# FLASH register map
Vendor: Texas Instruments
Registers are 32-bit, read-write, no defined reset value unless marked. A register's access mark holds for its fields unless they carry their own. Offsets are as the file gives them; [hi:lo] are bit positions; lines under a group give offsets from that group; {n}, {i} and the like mark numbered series; 'fields as' and 'values as' point back to an identical list.

## FLASH (part 2 of 2) — This is the MMR space for the flash wrapper. The flash wrapper is targeting multiple microcontroller platforms. The flash wrapper is a module that manages complex flash read, program and erase memory operations. The system is also given direct access to read flash memory contents directly for each instantiated flash bank through FBAP ports.
{0x30+4i} CMDDATA{i} (i=20..23) — Command Data Register {i} This register forms the data for a command. For DATAWIDTH == 128: This register represents bits {32i-609}:{32i-640} of flash word data register 5. This register is blocked for writes after a 1 is written to the CMDEXEC register and prior to STATCMD.DONE being set by the flash wrapper hardware. This register is used to aggregate masking for bits that do not require additional program pulses during program operations, and will be written to all 1 after the completion of all flash wrapper commands. Use cases for the CMDDATA* registers are as follows: 1) Program - These registers contain the data to be programmed. 2) Erase - These registers are not used.
  [31:0] VAL — A 32-bit data value is placed in this field.
    0xFFFFFFFF=MAXIMUM (Maximum value of [VAL]); 0=MINIMUM (Minimum value of [VAL])
0x80 CPU_CONNECT_0 — Directly connect peripheral publisher port to application processor
  [1] CPUSS0_CONN — CPUSS0 connect bit.
    0=UNCONNECTED (The CPU is not connected.); 1=CONNECTED (The CPU is connected.)
0x90 CMDDATA24 — Command Data Register 24 This register forms the data for a command. For DATAWIDTH == 128: This register represents bits 31:0 of flash word data register 6. This register is blocked for writes after a 1 is written to the CMDEXEC register and prior to STATCMD.DONE being set by the flash wrapper hardware. This register is used to aggregate masking for bits that do not require additional program pulses during program operations, and will be written to all 1 after the completion of all flash wrapper commands. Use cases for the CMDDATA* registers are as follows: 1) Program - These registers contain the data to be programmed. 2) Erase - These registers are not used.
  fields as CMDDATA20
0x94 CMDDATA25 — Command Data Register 25 This register forms the data for a command. For DATAWIDTH == 128: This register represents bits 63:32 of flash word data register 6. This register is blocked for writes after a 1 is written to the CMDEXEC register and prior to STATCMD.DONE being set by the flash wrapper hardware. This register is used to aggregate masking for bits that do not require additional program pulses during program operations, and will be written to all 1 after the completion of all flash wrapper commands. Use cases for the CMDDATA* registers are as follows: 1) Program - These registers contain the data to be programmed. 2) Erase - These registers are not used.
  fields as CMDDATA20
0x98 CMDDATA26 — Command Data Register 26 This register forms the data for a command. For DATAWIDTH == 128: This register represents bits 95:64 of flash word data register 6. This register is blocked for writes after a 1 is written to the CMDEXEC register and prior to STATCMD.DONE being set by the flash wrapper hardware. This register is used to aggregate masking for bits that do not require additional program pulses during program operations, and will be written to all 1 after the completion of all flash wrapper commands. Use cases for the CMDDATA* registers are as follows: 1) Program - These registers contain the data to be programmed. 2) Erase - These registers are not used..
  fields as CMDDATA20
0x9C CMDDATA27 — Command Data Register 27 This register forms the data for a command. For DATAWIDTH == 128: This register represents bits 127:96 of flash word data register 6. This register is blocked for writes after a 1 is written to the CMDEXEC register and prior to STATCMD.DONE being set by the flash wrapper hardware. This register is used to aggregate masking for bits that do not require additional program pulses during program operations, and will be written to all 1 after the completion of all flash wrapper commands. Use cases for the CMDDATA* registers are as follows: 1) Program - These registers contain the data to be programmed. 2) Erase - These registers are not used.
  fields as CMDDATA20
{0x30+4i} CMDDATA{i} (i=28..31) — Command Data Register {i} This register forms the data for a command. For DATAWIDTH == 128: This register represents bits {32i-865}:{32i-896} of flash word data register 7. This register is blocked for writes after a 1 is written to the CMDEXEC register and prior to STATCMD.DONE being set by the flash wrapper hardware. This register is used to aggregate masking for bits that do not require additional program pulses during program operations, and will be written to all 1 after the completion of all flash wrapper commands. Use cases for the CMDDATA* registers are as follows: 1) Program - These registers contain the data to be programmed. 2) Erase - These registers are not used.
  fields as CMDDATA20
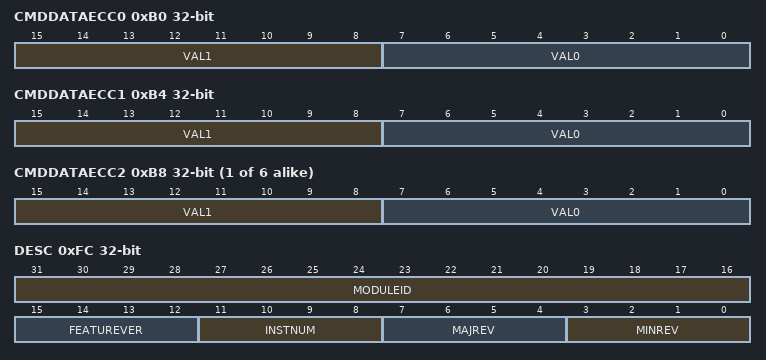
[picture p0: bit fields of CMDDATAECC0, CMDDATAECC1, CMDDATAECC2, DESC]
0xB0 CMDDATAECC0 — Command Data Register 0 This register forms the ECC portion of the data for a command. This ECC data in this register covers flash data register 0. The hardware ECC generation in flash wrapper can be overridden and ECC data developed elsewhere can be used. ECC data is placed in this register. This register is blocked for writes after a 1 is written to the CMDEXEC register and prior to STATCMD.DONE being set by the flash wrapper hardware. Use cases for the CMDDATA* registers are as follows: 1) Program - These registers contain the data to be programmed. 2) Erase - These registers are not used. This register is used to aggregate masking for bits that do not require additional program pulses during program operations, and will be written to all 1 after the completion of all flash wrapper commands.
  [15:8] VAL1 — ECC data for bits 127:64 of the data is placed here.
    255=MAXIMUM (Maximum value); 0=MINIMUM (Minimum value)
  [7:0] VAL0 — ECC data for bits 63:0 of the data is placed here.
    255=MAXIMUM (Maximum value); 0=MINIMUM (Minimum value)
0xB4 CMDDATAECC1 — Command Data Register 1 This register forms the ECC portion of the data for a command. This ECC data in this register covers flash data register 0. The hardware ECC generation in flash wrapper can be overridden and ECC data developed elsewhere can be used. ECC data is placed in this register. This register is blocked for writes after a 1 is written to the CMDEXEC register and prior to STATCMD.DONE being set by the flash wrapper hardware. Use cases for the CMDDATA* registers are as follows: 1) Program - These registers contain the data to be programmed. 2) Erase - These registers are not used. This register is used to aggregate masking for bits that do not require additional program pulses during program operations, and will be written to all 1 after the completion of all flash wrapper commands.
  fields as CMDDATAECC0
{0xB0+4i} CMDDATAECC{i} (i=2..7) — Command Data Register {i} This register forms the ECC portion of the data for a command. This ECC data in this register covers flash data register {i}. The hardware ECC generation in flash wrapper can be overridden and ECC data developed elsewhere can be used. ECC data is placed in this register. This register is blocked for writes after a 1 is written to the CMDEXEC register and prior to STATCMD.DONE being set by the flash wrapper hardware. Use cases for the CMDDATA* registers are as follows: 1) Program - These registers contain the data to be programmed. 2) Erase - These registers are not used. This register is used to aggregate masking for bits that do not require additional program pulses during program operations, and will be written to all 1 after the completion of all flash wrapper commands.
  fields as CMDDATAECC0
0xD0 CMDWEPROTA — Command WriteErase Protect A Register This register allows the first 32 sectors of the main region to be protected from program or erase, with 1 bit protecting each sector. If the main region size is smaller than 32 sectors, then this register provides protection for the whole region. This register is blocked for writes after a 1 is written to the CMDEXEC register and prior to STATCMD.DONE being set by the flash wrapper hardware. In addition, this register is used to aggregate masking for sectors that do not require additional erase pulses during bank erase operations, and will be written to all 1 after the completion of all flash wrapper commands.
  [31:0] VAL — Each bit protects 1 sector. bit [0]: When 1, sector 0 of the flash memory will be protected from program and erase. bit [1]: When 1, sector 1 of the flash memory will be protected from program and erase. : : bit [31]: When 1, sector 31 of the flash memory will be protected from program and erase.
    values as CMDDATA20.VAL
0xD4 CMDWEPROTB — Command WriteErase Protect B Register This register allows main region sectors to be protected from program and erase. Each bit corresponds to a group of 8 sectors. There are multiple cases for how these protect bits are applied: 1. Single-bank system, CMDWEPROTA register present: The first 32 sectors are protected via the CMDWEPROTA register. Thus, the protection given by the bits in CMDWEPROTB begin with sector 32. 2. Single-bank system, CMDWEPROTA register not present: The protection given by the bits in CMDWEPROTB begin with sector 0. 3. Multi-bank system, CMDWEPROTA register present - Bank 0: The first 32 sectors of bank 0 are protected via the CMDWEPROTA register. Thus, only bits 4 and above of CMDWEPROTB would be applicable to bank 0. The protection of bit 4 and above would begin at sector 32. Bits 3:0 of WEPROTB are ignored for bank 0. 4. Multi-bank system, CMDWEPROTA register present, Banks 1-N: For banks other than bank 0 in a multi-bank system, CMDWEPROTA has no effect, so the bits in CMDWEPROTB will protect these banks starting from sector 0. 5. Multi-bank system, CMDWEPROTA register not present: The bits in CMDWEPROTB will protect any of the banks starting from sector 0. This register is blocked for writes after a 1 is written to the CMDEXEC register and prior to STATCMD.DONE being set by the flash wrapper hardware. In addition, this register is used to aggregate masking for sectors that do not require additional erase pulses during bank erase operations, and will be written to all 1 after the completion of all flash wrapper commands.
  [31:0] VAL — Each bit protects a group of 8 sectors. When a bit is 1, the associated 8 sectors in the flash will be protected from program and erase. A maximum of 256 sectors can be protected with this register.
    values as CMDDATA20.VAL
0xD8 CMDWEPROTC — Command WriteErase Protect C Register This register allows main region sectors to be protected from program and erase. Each bit corresponds to a group of 8 sectors. This register extends the protection bits from the CMDWEPROTB register to cover bank sizes larger than 32*8=256 sectors. This register is blocked for writes after a 1 is written to the CMDEXEC register and prior to STATCMD.DONE being set by the flash wrapper hardware. In addition, this register is used to aggregate masking for sectors that do not require additional erase pulses during bank erase operations, and will be written to all 1 after the completion of all flash wrapper commands.
  [31:0] VAL — Each bit protects a group of 8 sectors. When a bit is 1, the associated 8 sectors in the flash will be protected from program and erase. Note that the sectors protected with this register start at sector 256 in the flash, where the sectors protected by the CMDWEPROTB register end.
    values as CMDDATA20.VAL
0xE0 EVT_MODE ro — Event mode register. It is used to select whether each line is disabled, in software mode (software clears the RIS) or in hardware mode (hardware clears the RIS).
  [1:0] INT0_CFG — Event line mode select for peripheral event
    0=DISABLE (The interrupt or event line is disabled.); 1=SOFTWARE (The interrupt or event line is in software mode. Software must clear the RIS.); 2=HARDWARE (The interrupt or event line is in hardware mode. Hardware must clear the RIS.)
0xFC DESC ro — Hardware Version Description Register: This register identifies the flash wrapper hardware version and feature set used.
  [31:16] MODULEID
    0xFFFF=MAXIMUM (Highest possible value); 0=MINIMUM (Smallest value)
  [15:12] FEATUREVER — Feature set
    15=MAXIMUM (Maximum Value); 0=MINIMUM (Minimum Value)
  [11:8] INSTNUM — Instance number
    15=MAXIMUM (Highest possible value); 0=MINIMUM (Smallest value)
  [7:4] MAJREV — Major Revision
    values as INSTNUM
  [3:0] MINREV — Minor Revision
    values as INSTNUM
0x100 TRIMCTL — Allows control of the application of bank/pump trim values.
  [0] ENABLE — Indicate that Bank and Pump trim values are valid.
    0=INVALID (Trim data is not valid); 1=VALID (Trim data is valid)
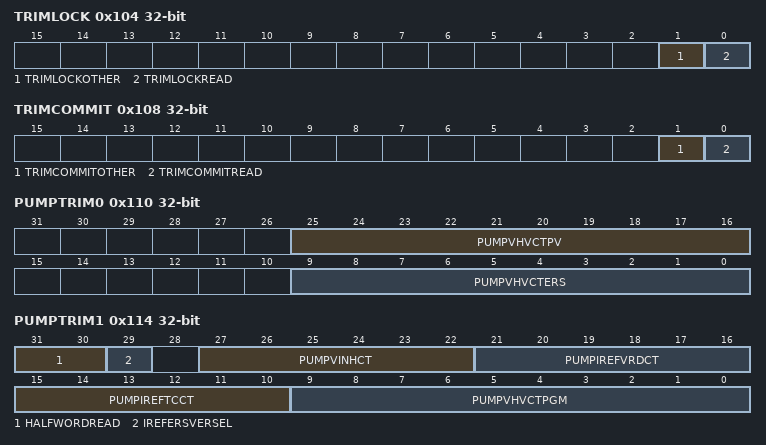
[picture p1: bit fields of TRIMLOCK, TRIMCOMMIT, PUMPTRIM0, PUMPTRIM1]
0x104 TRIMLOCK — Trim Lock Register When set PUMPTRIM* and BANK*TRIM* registers are locked and cannot be written.
  [1] TRIMLOCKOTHER — This bit controls the PUMPTRIM and BANK*TRIM registers.
    0=UNLOCKED (*TRIM registers are open for write.); 1=LOCKED (*TRIM registers are locked from write)
  [0] TRIMLOCKREAD — This bit controls the PUMPTRIMREAD and BANK*TRIMREAD registers.
    0=UNLOCKED (*TRIMREAD registers are open for write.); 1=LOCKED (*TRIMREAD registers are locked from write)
0x108 TRIMCOMMIT — Trim Commit Register When bits in this register are set, all associated trim registers (including TRIMCTL, TRIMLOCK and this register) are locked from update. Only a reset will unlock this register.
  [1] TRIMCOMMITOTHER — This bit controls the PUMPTRIM and BANK*TRIM registers.
    0=UNCOMMITTED (*TRIM registers are not committed.); 1=COMMITTED (*TRIM registers are committed)
  [0] TRIMCOMMITREAD — This bit controls the PUMPTRIMREAD and BANK*TRIMREAD registers.
    0=UNCOMMITTED (*TRIMREAD registers are not committed.); 1=COMMITTED (*TRIMREAD registers are committed)
0x110 PUMPTRIM0 — Pump Trim 0 Register. This register contains pump trim values associated with program and erase.
  [25:16] PUMPVHVCTPV — VHVCT pump trim value for program verify
    0x3FF=MAXIMUM (Maximum value of [PUMPVHVCTPV]); 0=MINIMUM (Minimum value of [PUMPVHVCTPV])
  [9:0] PUMPVHVCTERS — VHVCT pump trim value for erase
    0x3FF=MAXIMUM (Maximum value of [PUMPVHVCTERS]); 0=MINIMUM (Minimum value of [PUMPVHVCTERS])
0x110 CMDWEPROTNM — Command WriteErase Protect Non-Main Register This register allows non-main region region sectors to be protected from program and erase. Each bit corresponds to 1 sector. This register is blocked for writes after a 1 is written to the CMDEXEC register and prior to STATCMD.DONE being set by the flash wrapper hardware. In addition, this register is used to aggregate masking for sectors that do not require additional erase pulses during bank erase operations, and will be written to all 1 after the completion of all flash wrapper commands.
  [31:0] VAL — Each bit protects 1 sector. bit [0]: When 1, sector 0 of the non-main region will be protected from program and erase. bit [1]: When 1, sector 1 of the non-main region will be protected from program and erase. : : bit [31]: When 1, sector 31 of the non-main will be protected from program and erase.
    values as CMDDATA20.VAL
0x114 PUMPTRIM1 — Pump Trim 1 Register. This register contains pump trim values associated with program and erase.
  [31:30] HALFWORDREAD — NoWrapper half-word read disable
    3=HALFWORDDIS (Half word read disabled for EraseVerify Half word read disabled for ReadVerify/ProgramVerify); 2=HALFWORDEN_PVRV (Half word read disabled for EraseVerify Half word read enabled for ReadVerify/ProgramVerify); 1=HALFWORDEN_EV (Half word read enabled for EraseVerify Half word read disabled for ReadVerify/ProgramVerify); 0=HALFWORDEN_EV_PVRV (Half word read enabled for EraseVerify Half word read enabled for ReadVerify/ProgramVerify)
  [29] IREFERSVERSEL — Indicates low or high setting for IREF used for erase verify mode in all banks
    0=LOWIREF (IREF set to lower value (higher value * 2/3)); 1=HIGHIREF (IREF set to higher value.)
  [27:22] PUMPVINHCT — VINHCT pump trim value
    63=MAXIMUM (Maximum value of [PUMPVINHCT]); 0=MINIMUM (Minimum value of [PUMPVINHCT])
  [21:16] PUMPIREFVRDCT — IREFVRDCT pump trim value
    31=MAXIMUM (Maximum value of [PUMPIREFVRDCT]); 0=MINIMUM (Minimum value of [PUMPIREFVRDCT])
  [15:10] PUMPIREFTCCT — IREFTCCT pump trim value
    31=MAXIMUM (Maximum value of [PUMPIREFTCCT]); 0=MINIMUM (Minimum value of [PUMPIREFTCCT])
  [9:0] PUMPVHVCTPGM — VHVCT pump trim value for program
    0x3FF=MAXIMUM (Maximum value of [PUMPVHVCTPGM]); 0=MINIMUM (Minimum value of [PUMPVHVCTPGM])
0x114 CMDWEPROTTR — Command WriteErase Protect Trim Register This register allows trim region sectors to be protected from program and erase. Each bit corresponds to 1 sector. This register is blocked for writes after a 1 is written to the CMDEXEC register and prior to STATCMD.DONE being set by the flash wrapper hardware. In addition, this register is used to aggregate masking for sectors that do not require additional erase pulses during bank erase operations, and will be written to all 1 after the completion of all flash wrapper commands.
  [31:0] VAL — Each bit protects 1 sector. bit [0]: When 1, sector 0 of the engr region will be protected from program and erase. bit [1]: When 1, sector 1 of the engr region will be protected from program and erase. : : bit [31]: When 1, sector 31 of the engr region will be protected from program and erase.
    values as CMDDATA20.VAL
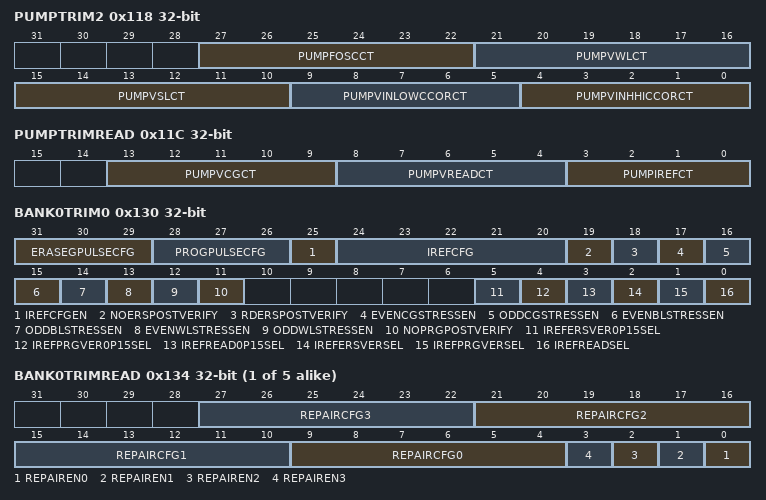
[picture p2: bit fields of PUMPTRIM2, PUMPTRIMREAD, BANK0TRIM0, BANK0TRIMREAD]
0x118 PUMPTRIM2 — Pump Trim 2 Register. This register contains pump trim values associated with program and erase.
  [27:22] PUMPFOSCCT — FOSCCT pump trim value
    63=MAXIMUM (Maximum value of [PUMPFOSCCT]); 0=MINIMUM (Minimum value of [PUMPFOSCCT])
  [21:16] PUMPVWLCT — VWLCT pump trim value
    63=MAXIMUM (Maximum value of [PUMPVWLCT]); 0=MINIMUM (Minimum value of [PUMPVWLCT])
  [15:10] PUMPVSLCT — VSLCT pump trim value
    63=MAXIMUM (Maximum value of [PUMPVSLCT]); 0=MINIMUM (Minimum value of [PUMPVSLCT])
  [9:5] PUMPVINLOWCCORCT — VINLOWCCORCT pump trim value
    31=MAXIMUM (Maximum value of [PUMPVINLOWCCORCT]); 0=MINIMUM (Minimum value of [PUMPVINLOWCCORCT])
  [4:0] PUMPVINHHICCORCT — VINHHICCORCT pump trim value
    31=MAXIMUM (Maximum value of [PUMPVINHHICCORCT]); 0=MINIMUM (Minimum value of [PUMPVINHHICCORCT])
0x118 CMDWEPROTEN — Command WriteErase Protect Engr Register This register allows engr region sectors to be protected from program and erase. Each bit corresponds to 1 sector. This register is blocked for writes after a 1 is written to the CMDEXEC register and prior to STATCMD.DONE being set by the flash wrapper hardware. In addition, this register is used to aggregate masking for sectors that do not require additional erase pulses during bank erase operations, and will be written to all 1 after the completion of all flash wrapper commands.
  fields as CMDWEPROTTR
0x11C PUMPTRIMREAD — Pump Read Trim Register. This register contains pump trim values which apply to flash reads.
  [13:9] PUMPVCGCT — VCGCT pump trim value
    31=MAXIMUM (Maximum value of [PUMPVCGCT]); 0=MINIMUM (Minimum value of [PUMPVCGCT])
  [8:4] PUMPVREADCT — VREADCT pump trim value
    31=MAXIMUM (Maximum value of [PUMPVREADCT]); 0=MINIMUM (Minimum value of [PUMPVREADCT])
  [3:0] PUMPIREFCT — IREFCT pump trim value
    15=MAXIMUM (Maximum value of [PUMPIREFCT]); 0=MINIMUM (Minimum value of [PUMPIREFCT])
0x130 BANK0TRIM0 — Bank 0 Trim 0 Register. Contains bits [31:0] of the bank 0 trim.
  [31:29] ERASEGPULSECFG — Configures the length of the erase pulse. By default, the erase pulse time is fixed. When the SKIPPOSTVERIFY bit is set, the configuration in this field is used for the erase pulse length.
    7=USE50MS (Use 50ms for the erase pulse time); 6=USE25MS (Use 25ms for the erase pulse time); 5=USE700MS (Use 700ms for the erase pulse time); 4=USE500MS (Use 500ms for the erase pulse time); 3=USE400MS (Use 400ms for the erase pulse time); 2=USE300MS (Use 300ms for the erase pulse time); 1=USE200MS (Use 200ms for the erase pulse time); 0=USE100MS (Use 100ms for the erase pulse time)
  [28:26] PROGPULSECFG — Configures the length of the program pulse. By default, the program pulse time is fixed. When the SKIPPOSTVERIFY bit is set, the configuration in this field is used for the program pulse length.
    7=USE1XDEFAULT (Use 1.0 X the default, fixed program pulse time); 6=USE0P5XDEFAULT (Use 0.5 X the default, fixed program pulse time); 5=USE5XDEFAULT (Use 5.0 X the default, fixed program pulse time); 4=USE4XDEFAULT (Use 4.0 X the default, fixed program pulse time); 3=USE3XDEFAULT (Use 3.0 X the default, fixed program pulse time); 2=USE2P5XDEFAULT (Use 2.5 X the default, fixed program pulse time); 1=USE2XDEFAULT (Use 2.0 X the default, fixed program pulse time); 0=USE1P5XDEFAULT (Use 1.5 X the default, fixed program pulse time)
  [25] IREFCFGEN — Enables override of IREF configuration. By default, this is controlled by the mode setting in the bank. If this bit is set, the mode setting will be ignored, and the value encoded into the IREFCFG field will be used to configure the IREF on the reference side.
    0=DISABLED (Feature disabled); 1=ENABLED (Feature enabled)
  [24:20] IREFCFG — Configures IREF used for read operation
    16=USE3XIREF (Adds 3.00*IREF (nominally 4uA to bank) to the IREF current on the reference side); 8=USE2XIREF (Adds 2.00*IREF (nominally 4uA to bank) to the IREF current on the reference side); 4=USE1XIREF (Adds 1.00*IREF (nominally 4uA to bank) to the IREF current on the reference side); 2=USE0P5XIREF (Adds 0.50*IREF (nominally 4uA to bank) to the IREF current on the reference side); 1=USE0P25XIREF (Adds 0.25*IREF (nominally 4uA to bank) to the IREF current on the reference side); 0=DEFAULTIREF (Uses default IREF on the reference side)
  [19] NOERSPOSTVERIFY — Do not do a post verify after erase.
    0=DISABLED (Feature disabled); 1=ENABLED (Feature enabled)
  [18] RDERSPOSTVERIFY — Use READ mode for erase verify operations.
    0=DISABLED (Feature disabled); 1=ENABLED (Feature enabled)
  [17] EVENCGSTRESSEN — Even control gate stress enable
    0=DISABLED (Feature disabled); 1=ENABLED (Feature enabled)
  [16] ODDCGSTRESSEN — Odd control gate stress enable
    0=DISABLED (Feature disabled); 1=ENABLED (Feature enabled)
  [15] EVENBLSTRESSEN — Even bit line stress enable
    0=DISABLED (Feature disabled); 1=ENABLED (Feature enabled)
  [14] ODDBLSTRESSEN — Odd bit line stress enable
    0=DISABLED (Feature disabled); 1=ENABLED (Feature enabled)
  [13] EVENWLSTRESSEN — Even word line stress enable
    0=DISABLED (Feature disabled); 1=ENABLED (Feature enabled)
  [12] ODDWLSTRESSEN — Odd word line stress enable
    0=DISABLED (Feature disabled); 1=ENABLED (Feature enabled)
  [11] NOPRGPOSTVERIFY — Do not do a post verify after program.
    0=DISABLED (Feature disabled); 1=ENABLED (Feature enabled)
  [5] IREFERSVER0P15SEL — Indicates low or high setting for IREF used for erase verify mode. High setting is 15% higher than low setting.
    values as PUMPTRIM1.IREFERSVERSEL
  [4] IREFPRGVER0P15SEL — Indicates low or high setting for IREF used for program verify mode. High setting is 15% higher than low setting.
    values as PUMPTRIM1.IREFERSVERSEL
  [3] IREFREAD0P15SEL — Indicates low or high setting for IREF used for read modes. High setting is 15% higher than low setting.
    0=LOWIREF (IREF set to nominal value); 1=HIGHIREF (IREF set to nominal value + 10%.)
  [2] IREFERSVERSEL — Indicates low or high setting for IREF used for erase verify mode. High setting is 50% higher than low setting.
    values as PUMPTRIM1.IREFERSVERSEL
  [1] IREFPRGVERSEL — Indicates low or high setting for IREF used for program verify mode. High setting is 50% higher than low setting.
    values as PUMPTRIM1.IREFERSVERSEL
  [0] IREFREADSEL — Indicates low or high setting for IREF used for read modes. High setting is 50% higher than low setting.
    values as PUMPTRIM1.IREFERSVERSEL
{0x134+0x10*i} BANK{i}TRIMREAD (i=0..4) — Bank {i} Read Trim Register. Contains repair trim bits for bank {i}.
  [6n+9:6n+4] REPAIRCFG{n} (n=0..3) — Repair Configure {n} Configures repair for bank data bits {36n+35}:{36n} (if ecc) or {32n+31}:{32n} (if no ecc). This field indicates which of the 36 (if ecc) or 32 (if no ecc) bits in the bank data word is replaced with a redundant bit for repair.
    35=MAXIMUM (Maximum value of [REPAIRCFG{n}]); 0=MINIMUM (Minimum value of [REPAIRCFG{n}])
  [n] REPAIREN{n} (n=0..3) — Repair Enable {n} Enables repair for bank data bits {36n+35}:{36n} (if ecc) or {32n+31}:{32n} (if no ecc)
    0=DISABLE; 1=ENABLE
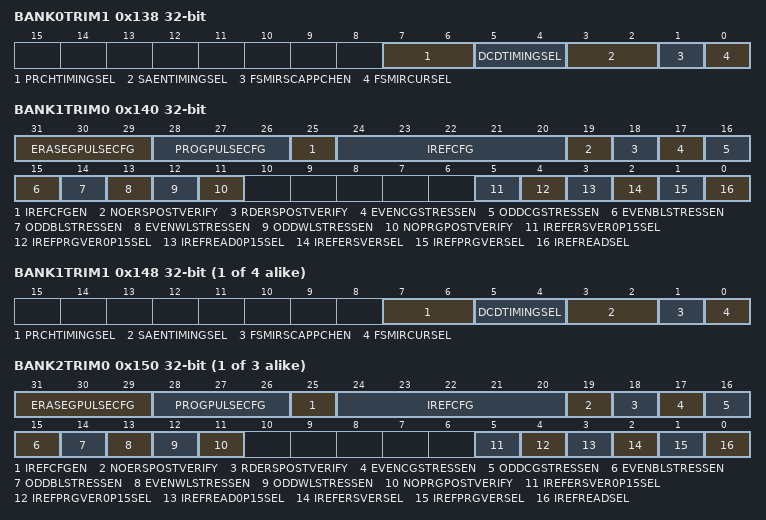
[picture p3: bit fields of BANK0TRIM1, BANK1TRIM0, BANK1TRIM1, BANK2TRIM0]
0x138 BANK0TRIM1 — Bank 0 Trim 1 Register. Contains bits [39:32] of the bank 0 trim (MP bank only)
  [7:6] PRCHTIMINGSEL — Select delay for bitline precharge
    3=FASTTIMING (Faster timing by 1x time step (1 x 0.4 ns at worst timing corner)); 2=NOMINAL (Nominal timing delay); 1=SLOWTIMING (Slower timing by 1x time step (1 x 0.4 ns at worst timing corner)); 0=SLOWX2TIMING (Slower timing by 2x time step (2 x 0.4 ns at worst timing corner))
  [5:4] DCDTIMINGSEL — Select delay for address decode.
    0=SLOWX2TIMING (Slower timing by 2x time step (2 x 0.4 ns at worst timing corner)); 3=FASTTIMING (Faster timing by 1x time step (1 x 0.4 ns at worst timing corner)); 1=SLOWTIMING (Slower timing by 1x time step (1 x 0.4 ns at worst timing corner)); 2=NOMINAL (Nominal timing delay)
  [3:2] SAENTIMINGSEL — Select delay for sense amp enable
    3=FASTX2TIMING (Faster timing by 2x time step (2 x 0.5 ns at worst timing corner)); 2=FASTTIMING (Faster timing by 1x time step (1 x 0.5 ns at worst timing corner)); 0=SLOWTIMING (Slower timing by 1x time step (1 x 0.5 ns at worst timing corner)); 1=NOMTIMING (Nominal timing delay)
  [1] FSMIRSCAPPCHEN — Enable for stabilization capacitance pre-charge at fast startup current mirror
    0=DISABLE; 1=ENABLE
  [0] FSMIRCURSEL — Select for quiescent current at fast startup current mirror
    0=NOMCUR (Enables nominal quiescent current); 1=LOWCUR (Enables low quiescent current)
0x140 BANK1TRIM0 — Bank 1 Trim 0 Register. Contains bits [31:0] of the bank 0 trim.
  fields as BANK0TRIM0
{0x138+0x10*i} BANK{i}TRIM1 (i=1..4) — Bank {i} Trim 1 Register. Contains bits [39:32] of the bank 0 trim (MP bank only)
  [7:6] PRCHTIMINGSEL — Select delay for bitline precharge
    values as BANK0TRIM1.PRCHTIMINGSEL
  [5:4] DCDTIMINGSEL — Select delay for address decode.
    values as BANK0TRIM1.PRCHTIMINGSEL
  [3:2] SAENTIMINGSEL — Select delay for sense amp enable
    3=FASTX2TIMING (Faster timing by 2x time step (2 x 0.5 ns at worst timing corner)); 2=FASTTIMING (Faster timing by 1x time step (1 x 0.5 ns at worst timing corner)); 1=NOMTIMING (Nominal timing delay); 0=SLOWTIMING (Slower timing by 1x time step (1 x 0.5 ns at worst timing corner))
  [1] FSMIRSCAPPCHEN — Enable for stabilization capacitance pre-charge at fast startup current mirror
    0=DISABLE; 1=ENABLE
  [0] FSMIRCURSEL — Select for quiescent current at fast startup current mirror
    values as BANK0TRIM1.FSMIRCURSEL
{0x130+0x10*i} BANK{i}TRIM0 (i=2..4) — Bank {i} Trim 0 Register. Contains bits [31:0] of the bank {i} trim.
  fields as BANK0TRIM0
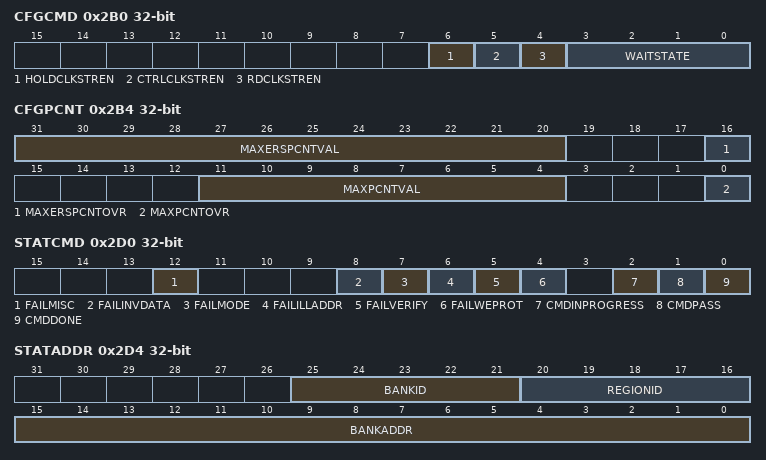
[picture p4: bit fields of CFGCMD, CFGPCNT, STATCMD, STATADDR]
0x2B0 CFGCMD — Command Configuration Register This register configures specific capabilities of the state machine for related to the execution of a command. This register is blocked for writes after CMDEXEC is written to a 1 and prior to STATCMD.DONE being set by the hardware to indicate that command execution has completed.
  [6] HOLDCLKSTREN — Enable pulse stretching for the clocking of the hold latches for inputs to the flash bank. This effectively divides the flash controller internal clock in order to create a 50/50 duty cycle clock for hold latching.
    0=DISABLE; 1=ENABLE
  [5] CTRLCLKSTREN — Enable pulse stretching when generating a control clock to the flash bank from the flash wrapper. This effectively divides the control clock driven to the bank in order to avoid minimum pulse width requirements at the bank.
    0=DISABLE; 1=ENABLE
  [4] RDCLKSTREN — Enable pulse stretching when generating a read clock to the flash bank from the flash wrapper. This effectively divides the read clock driven to the bank in order to avoid minimum pulse width requirements at the bank.
    0=DISABLE; 1=ENABLE
  [3:0] WAITSTATE — Wait State setting for verify reads
    15=MAXIMUM (Maximum value); 0=MINIMUM (Minimum value)
0x2B4 CFGPCNT — Pulse Counter Configuration Register This register allows further configuration of maximum pulse counts for program and erase operations. This register is blocked for writes after a 1 is written to the CMDEXEC register and prior to STATCMD.DONE being set by the flash wrapper hardware.
  [31:20] MAXERSPCNTVAL — Override maximum pulse count for erase with this value. If MAXERSPCNTOVR = 0, then this field is ignored. If MAXERSPCNTOVR = 1, then this value will be used to override the max pulse count for erase.
    0xFFF=MAXIMUM (Maximum value); 0=MINIMUM (Minimum value)
  [16] MAXERSPCNTOVR — Override hard-wired maximum pulse count for erase. If set, then the value in MAXERSPCNTVAL will be used as the max pulse count for erase operations. By default, this bit is 0, and a hard-wired max pulse count is used.
    0=DEFAULT (Use hard-wired (default) value for maximum pulse count); 1=OVERRIDE (Use value from MAXERSPCNTVAL field as maximum erase pulse count)
  [11:4] MAXPCNTVAL — Override maximum pulse counter with this value. If MAXPCNTOVR = 0, then this field is ignored. If MAXPCNTOVR = 1 and MAXERSPCNTOVR = 0, then this value will be used to override the max pulse count for both program and erase. Full max value will be {4'h0, MAXPCNTVAL} . If MAXPCNTOVR = 1 and MAXERSPCNTOVR = 1, then this value will be used to override the max pulse count for program only. Full max value will be {4'h0, MAXPCNTVAL}.
    255=MAXIMUM (Maximum value); 0=MINIMUM (Minimum value)
  [0] MAXPCNTOVR — Override hard-wired maximum pulse count. If MAXERSPCNTOVR is not set, then setting this value alone will override the max pulse count for both program and erase. If MAXERSPCNTOVR is set, then this bit will only control the max pulse count setting for program. By default, this bit is 0, and a hard-wired max pulse count is used.
    0=DEFAULT (Use hard-wired (default) value for maximum pulse count); 1=OVERRIDE (Use value from MAXPCNTVAL field as maximum puse count)
0x2D0 STATCMD ro — Command Status Register This register contains status regarding completion and errors of command execution.
  [12] FAILMISC — Command failed due to error other than write/erase protect violation or verify error. This is an extra bit in case a new failure mechanism is added which requires a status bit.
    0=STATNOFAIL (No Fail); 1=STATFAIL (Fail)
  [8] FAILINVDATA — Program command failed because an attempt was made to program a stored 0 value to a 1.
    0=STATNOFAIL (No Fail); 1=STATFAIL (Fail)
  [7] FAILMODE — Command failed because a bank has been set to a mode other than READ. Program and Erase commands cannot be initiated unless all banks are in READ mode.
    0=STATNOFAIL (No Fail); 1=STATFAIL (Fail)
  [6] FAILILLADDR — Command failed due to the use of an illegal address
    0=STATNOFAIL (No Fail); 1=STATFAIL (Fail)
  [5] FAILVERIFY — Command failed due to verify error
    0=STATNOFAIL (No Fail); 1=STATFAIL (Fail)
  [4] FAILWEPROT — Command failed due to Write/Erase Protect Sector Violation
    0=STATNOFAIL (No Fail); 1=STATFAIL (Fail)
  [2] CMDINPROGRESS — Command In Progress
    0=STATCOMPLETE (Complete); 1=STATINPROGRESS (In Progress)
  [1] CMDPASS — Command Pass - valid when CMD_DONE field is 1
    0=STATFAIL (Fail); 1=STATPASS (Pass)
  [0] CMDDONE — Command Done
    0=STATNOTDONE (Not Done); 1=STATDONE (Done)
0x2D4 STATADDR ro — Current Address Counter Value Read only register giving read access to the state machine current address. A bank id, region id and address are stored in this register and are incremented as necessary during execution of a command.
  [25:21] BANKID — Current Bank ID A bank indicator is stored in this register which represents the current bank on which the state machine is operating. There is 1 bit per bank.
    1=BANK0; 2=BANK1; 4=BANK2; 8=BANK3; 16=BANK4
  [20:16] REGIONID — Current Region ID A region indicator is stored in this register which represents the current flash region on which the state machine is operating.
    1=MAIN (Main Region); 2=NONMAIN (Non-Main Region); 4=TRIM (Trim Region); 8=ENGR (Engr Region)
  [15:0] BANKADDR — Current Bank Address A bank offset address is stored in this register.
    0xFFFF=MAXIMUM (Maximum value); 0=MINIMUM (Minimum value)
0x2D8 STATPCNT ro — Current Pulse Count Register: Read only register giving read access to the state machine current pulse count value for program/erase operations.
  [11:0] PULSECNT — Current Pulse Counter Value
    0xFFF=MAXIMUM (Maximum value); 0=MINIMUM (Minimum value)
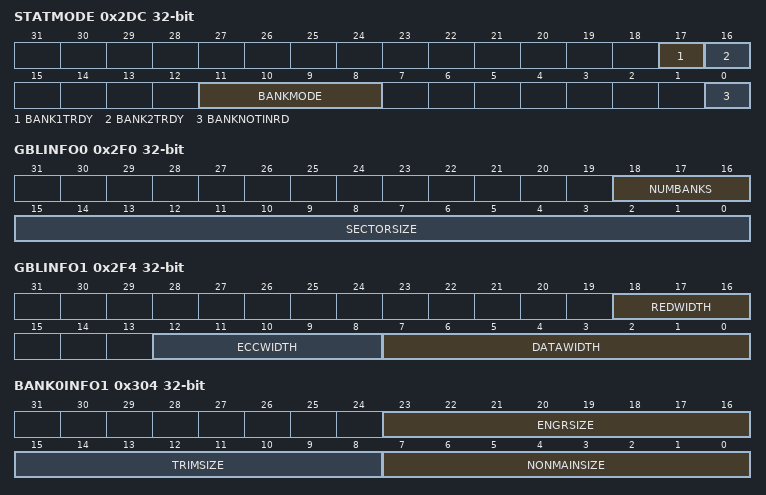
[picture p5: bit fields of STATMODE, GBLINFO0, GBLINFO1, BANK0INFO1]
0x2DC STATMODE ro — Mode Status Register Indicates one or more banks which not in READ mode, and it indicates the mode which the bank(s) are in.
  [17] BANK1TRDY — Bank 1T Ready. Bank(s) are ready for 1T access. This is accomplished when the bank and pump have been trimmed.
    0=FALSE (Not ready); 1=TRUE (Ready)
  [16] BANK2TRDY — Bank 2T Ready. Bank(s) are ready for 2T access. This is accomplished when the pump has fully driven power rails to the bank(s).
    0=FALSE (Not ready); 1=TRUE (Ready)
  [11:8] BANKMODE — Indicates mode of bank(s) that are not in READ mode
    0=READ (Read Mode); 2=RDMARG0 (Read Margin 0 Mode); 4=RDMARG1 (Read Margin 1 Mode); 6=RDMARG0B (Read Margin 0B Mode); 7=RDMARG1B (Read Margin 1B Mode); 9=PGMVER (Program Verify Mode); 10=PGMSW (Program Single Word); 11=ERASEVER (Erase Verify Mode); 12=ERASESECT (Erase Sector); 14=PGMMW (Program Multiple Word); 15=ERASEBNK (Erase Bank)
  [0] BANKNOTINRD — Bank not in read mode. Indicates which banks are not in READ mode. There is 1 bit per bank.
0x2F0 GBLINFO0 ro — Global Info 0 Register Read only register detailing information about sector size and number of banks present.
  [18:16] NUMBANKS — Number of banks instantiated Minimum: 1 Maximum: 5
    1=MINIMUM (Minimum value); 5=MAXIMUM (Maximum value)
  [15:0] SECTORSIZE — Sector size in bytes
    0x400=ONEKB (Sector size is ONEKB); 0x800=TWOKB (Sector size is TWOKB)
0x2F4 GBLINFO1 ro — Global Info 1 Register Read only register detailing information about data, ecc and redundant data widths in bits.
  [18:16] REDWIDTH — Redundant data width in bits
    0=W0BIT (Redundant data width is 0. Redundancy/Repair not present.); 2=W2BIT (Redundant data width is 2 bits); 4=W4BIT (Redundant data width is 4 bits)
  [12:8] ECCWIDTH — ECC data width in bits
    0=W0BIT (ECC data width is 0. ECC not used.); 8=W8BIT (ECC data width is 8 bits); 16=W16BIT (ECC data width is 16 bits)
  [7:0] DATAWIDTH — Data width in bits
    64=W64BIT (Data width is 64 bits); 128=W128BIT (Data width is 128 bits)
0x2F8 GBLINFO2 ro — Global Info 2 Register Read only register detailing information about the number of data registers present.
  [3:0] DATAREGISTERS — Number of data registers present.
    1=MINIMUM (Minimum value of [DATAREGISTERS]); 8=MAXIMUM (Maximum value of [DATAREGISTERS])
{0x300+0x10*i} BANK{i}INFO0 ro (i=0..2) — Bank Info 0 Register for bank {i}. Read only register detailing information about Main region size in the bank.
  [11:0] MAINSIZE — Main region size in sectors Minimum: 0x8 (8) Maximum: 0x200 (512)
    8=MINSECTORS (Minimum value of [MAINSIZE]); 0x200=MAXSECTORS (Maximum value of [MAINSIZE])
0x304 BANK0INFO1 ro — Bank Info1 Register for bank 0. Read only register detailing information about Non-Main, Trim, and Engr region sizes in the bank.
  [23:16] ENGRSIZE — Engr region size in sectors Minimum: 0x0 (0) Maximum: 0x10 (16)
    0=MINSECTORS (Minimum value of [ENGRSIZE]); 32=MAXSECTORS (Maximum value of [ENGRSIZE])
  [15:8] TRIMSIZE — Trim region size in sectors Minimum: 0x0 (0) Maximum: 0x10 (16)
    0=MINSECTORS (Minimum value of [TRIMSIZE]); 32=MAXSECTORS (Maximum value of [TRIMSIZE])
  [7:0] NONMAINSIZE — Non-main region size in sectors Minimum: 0x0 (0) Maximum: 0x10 (16)
    0=MINSECTORS (Minimum value of [NONMAINSIZE]); 32=MAXSECTORS (Maximum value of [NONMAINSIZE])
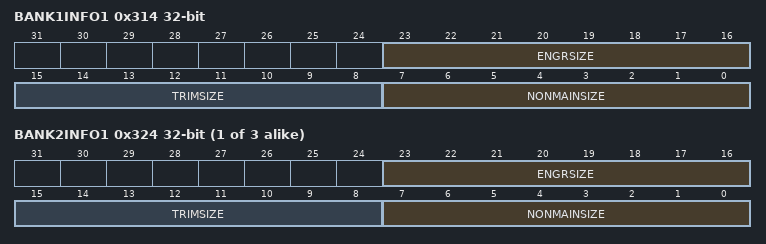
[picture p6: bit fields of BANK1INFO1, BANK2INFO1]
0x314 BANK1INFO1 ro — Bank Info1 Register for bank 1. Read only register detailing information about Non-Main, Trim, and Engr region sizes in the bank.
  [23:16] ENGRSIZE — Engr region size in sectors Minimum: 0x0 (0) Maximum: 0x10 (16)
    values as BANK0INFO1.ENGRSIZE
  [15:8] TRIMSIZE — Trim region size in sectors
    values as BANK0INFO1.TRIMSIZE
  [7:0] NONMAINSIZE — Non-main region size in sectors
    values as BANK0INFO1.NONMAINSIZE
{0x304+0x10*i} BANK{i}INFO1 ro (i=2..4) — Bank Info1 Register for bank {i}. Read only register detailing information about Non-Main, Trim, and Engr region sizes in the bank.
  [23:16] ENGRSIZE — Engr region size in sectors
    values as BANK0INFO1.ENGRSIZE
  [15:8] TRIMSIZE — Trim region size in sectors
    values as BANK0INFO1.TRIMSIZE
  [7:0] NONMAINSIZE — Non-main region size in sectors
    values as BANK0INFO1.NONMAINSIZE
0x330 BANK3INFO0 ro — Bank Info 0 Register for bank 3. Read only register detailing information about Main region size in the bank.
  [11:0] MAINSIZE — Main region size in sectors
    values as BANK0INFO0.MAINSIZE
0x340 BANK4INFO0 ro — Bank Info 0 Register for bank 4. Read only register detailing information about Main region size in the bank.
  fields as BANK3INFO0
